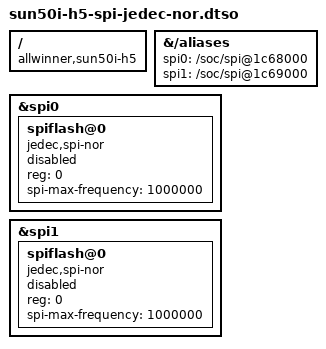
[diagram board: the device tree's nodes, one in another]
/dts-v1/;
/plugin/;

/ {
	compatible = "allwinner,sun50i-h5";

	fragment@0 {
		target-path = "/aliases";
		__overlay__ {
			spi0 = "/soc/spi@1c68000";
			spi1 = "/soc/spi@1c69000";
		};
	};

	fragment@1 {
		target = <&spi0>;
		__overlay__ {
			#address-cells = <1>;
			#size-cells = <0>;
			spiflash@0 {
				compatible = "jedec,spi-nor";
				reg = <0>;
				spi-max-frequency = <1000000>;
				status = "disabled";
			};
		};
	};

	fragment@2 {
		target = <&spi1>;
		__overlay__ {
			#address-cells = <1>;
			#size-cells = <0>;
			spiflash@0 {
				compatible = "jedec,spi-nor";
				reg = <0>;
				spi-max-frequency = <1000000>;
				status = "disabled";
			};
		};
	};
};
